# EMU_PRM register map
Vendor: Texas Instruments
Peripheral module from a debugger description file (folder omap34xx).
Registers are 32-bit, access per field, reset values left out (the file's numbers can be read two ways) unless marked. A register's access mark holds for its fields unless they carry their own. Offsets are as the file gives them; lines under a group give offsets from that group; [hi:lo] are bit positions; {n}, {i} and the like mark numbered series; 'fields as' and 'values as' point back to an identical list; <NAME> marks a mode.

## EMU_PRM
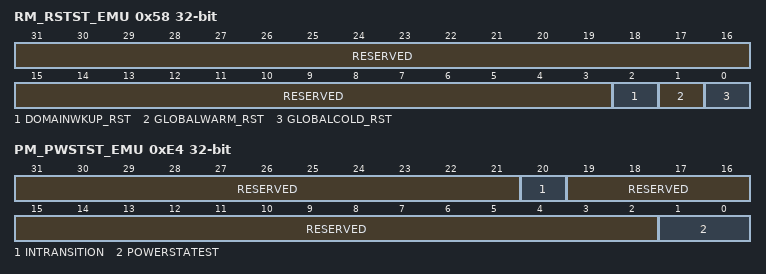
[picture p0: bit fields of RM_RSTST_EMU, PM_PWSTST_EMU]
0x58 RM_RSTST_EMU — This register logs the different reset sources of the EMU domain. Each bit is set upon release of the domain reset signal. Must be cleared by software.
  [31:3] RESERVED ro — Write 0s for future compatibility. Read returns 0.
  [2] DOMAINWKUP_RST rw — Power domain wake-up reset
    0=DOMAINWKUP_RST_0_r (No power domain wake-up reset.); 0=DOMAINWKUP_RST_0_w (Status bit unchanged); 1=DOMAINWKUP_RST_1_r (EMULATION domain has been reset following an EMULATION power domain wake-up.); 1=DOMAINWKUP_RST_1_w (Status bit is cleared to 0.)
  [1] GLOBALWARM_RST rw — Global warm reset
    0=GLOBALWARM_RST_0_r (No global warm reset.); 0=GLOBALWARM_RST_0_w (Status bit unchanged); 1=GLOBALWARM_RST_1_r (MPU domain has been reset upon a global warm reset); 1=GLOBALWARM_RST_1_w (Status bit is cleared to 0.)
  [0] GLOBALCOLD_RST rw — Global cold reset
    0=GLOBALCOLD_RST_0_r (No global cold reset.); 0=GLOBALCOLD_RST_0_w (Status bit unchanged); 1=GLOBALCOLD_RST_1_r (MPU domain has been reset upon a global cold reset); 1=GLOBALCOLD_RST_1_w (Status bit is cleared to 0.)
0xE4 PM_PWSTST_EMU ro — This register provides a status on the power state transition of the EMULATION domain.
  [31:21] RESERVED — Write 0s for future compatibility. Read returns 0.
  [20] INTRANSITION — Domain transition status
    0=No transition; 1=EMULATION power domain transition is in progress
  [19:2] RESERVED — Write 0x0040 for future compatibility. Read returns 0x0040.
  [1:0] POWERSTATEST — Current power state status
    0=Power domain is OFF; 3=Power domain is ON
